AUTOSAR XML (schema 4.0)
package /Powertrain
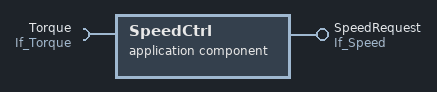
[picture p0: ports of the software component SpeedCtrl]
  application sw component type SpeedCtrl
    require port Torque: required-interface=If_Torque
    provide port SpeedRequest: provided-interface=If_Speed
